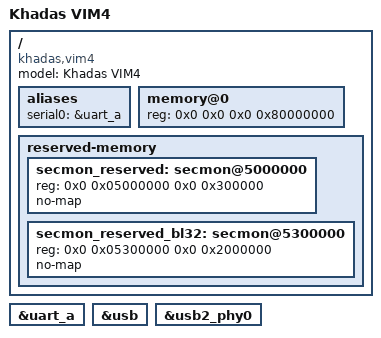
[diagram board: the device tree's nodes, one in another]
// SPDX-License-Identifier: (GPL-2.0+ OR MIT)
/dts-v1/;

#include "amlogic-t7.dtsi"

/ {
	model = "Khadas VIM4";
	compatible = "khadas,vim4", "amlogic,a311d2", "amlogic,t7";

	aliases {
		serial0 = &uart_a;
	};

	memory@0 {
		device_type = "memory";
		reg = <0x0 0x0 0x0 0x80000000>;
	};

	reserved-memory {
		#address-cells = <2>;
		#size-cells = <2>;
		ranges;

		secmon_reserved: secmon@5000000 {
			reg = <0x0 0x05000000 0x0 0x300000>;
			no-map;
		};

		secmon_reserved_bl32: secmon@5300000 {
			reg = <0x0 0x05300000 0x0 0x2000000>;
			no-map;
		};
	};
};

&uart_a {
	status = "okay";
};

&usb {
	status = "okay";
};

&usb2_phy0 {
	status = "okay";
};
